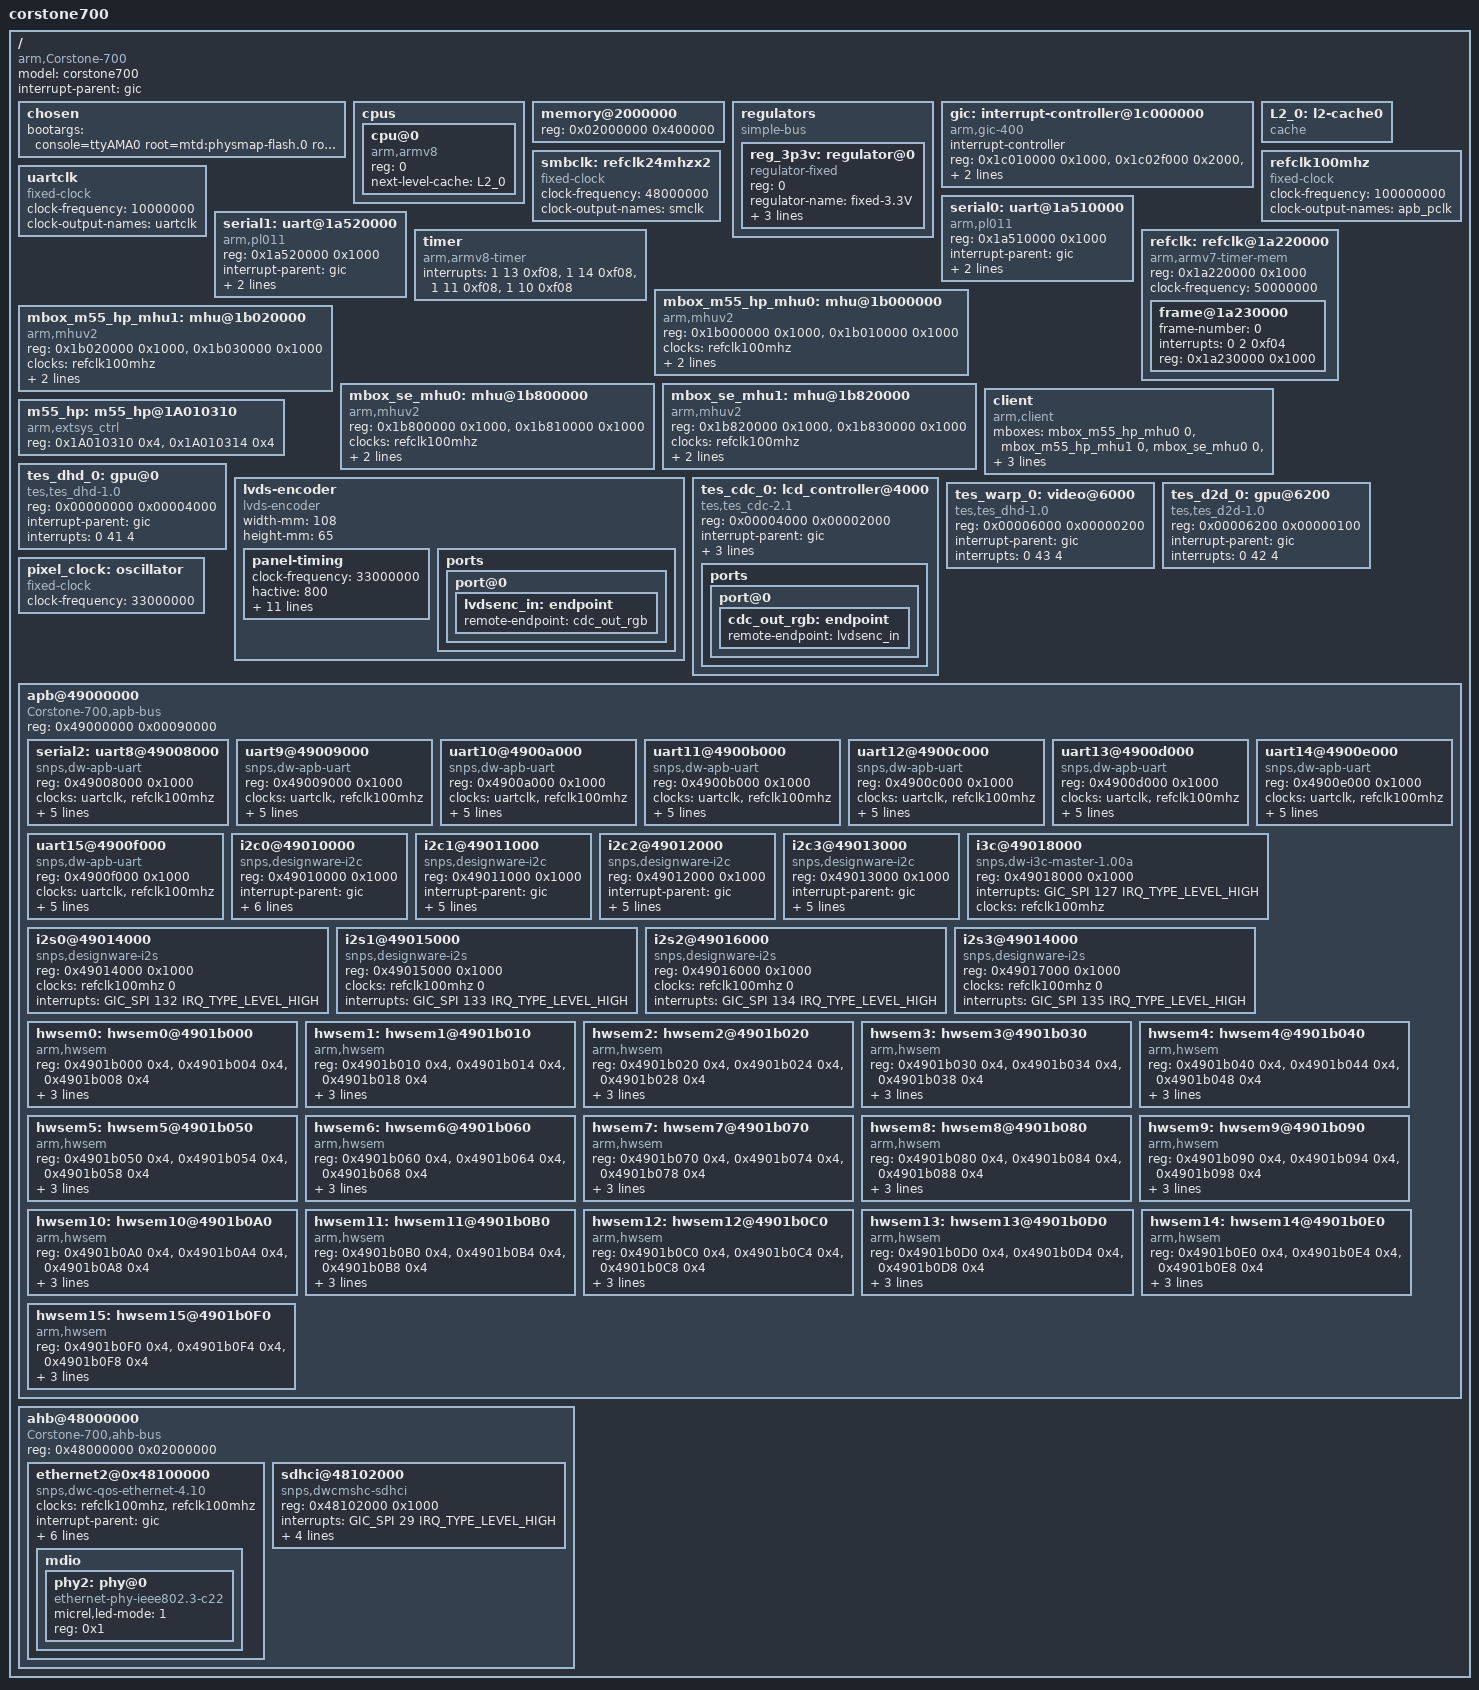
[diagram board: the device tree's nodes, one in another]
/*
 * Copyright (c) 2019, ARM Limited and Contributors. All rights reserved.
 *
 * SPDX-License-Identifier: BSD-3-Clause
 */

/dts-v1/;

#include <dt-bindings/interrupt-controller/arm-gic.h>

/ {
	model = "corstone700";
	compatible = "arm,Corstone-700";
	interrupt-parent = <&gic>;
	#address-cells = <1>;
	#size-cells = <1>;

	chosen {
		bootargs = "console=ttyAMA0 \
		root=mtd:physmap-flash.0 \
		ro \
		loglevel=9";
	};

	cpus {
		#address-cells = <1>;
		#size-cells = <0>;

		cpu@0 {
			device_type = "cpu";
			compatible = "arm,armv8";
			reg = <0>;
			next-level-cache = <&L2_0>;
		};
	};

	memory@2000000 {
		device_type = "memory";
		reg = <0x02000000 0x400000>;
	};

	regulators {
		compatible = "simple-bus";
		#address-cells = <1>;
		#size-cells = <0>;
		reg_3p3v: regulator@0 {
			compatible = "regulator-fixed";
			reg = <0>;
			regulator-name = "fixed-3.3V";
			regulator-min-microvolt = <3300000>;
			regulator-max-microvolt = <3300000>;
			regulator-always-on;
		};
	};

	gic: interrupt-controller@1c000000 {
		compatible = "arm,gic-400";
		#interrupt-cells = <3>;
		#address-cells = <0>;
		interrupt-controller;
		reg =	<0x1c010000 0x1000>,
			<0x1c02f000 0x2000>,
			<0x1c04f000 0x1000>,
			<0x1c06f000 0x2000>;
		interrupts = <1 9 0xf08>;
	};

	L2_0: l2-cache0 {
		compatible = "cache";
	};

	refclk100mhz: refclk100mhz {
		compatible = "fixed-clock";
		#clock-cells = <0>;
		clock-frequency = <100000000>;
		clock-output-names = "apb_pclk";
	};

	smbclk: refclk24mhzx2 {
		/* Reference 24MHz clock x 2 */
		compatible = "fixed-clock";
		#clock-cells = <0>;
		clock-frequency = <48000000>;
		clock-output-names = "smclk";
	};

	uartclk: uartclk {
		/* uart clock - 10MHz */
		compatible = "fixed-clock";
		#clock-cells = <0>;
		clock-frequency = <10000000>;
		clock-output-names = "uartclk";
	};

	serial0: uart@1a510000 {
		compatible = "arm,pl011", "arm,primecell";
		reg = <0x1a510000 0x1000>;
		interrupt-parent = <&gic>;
		interrupts = <0 19 4>;
		clocks = <&uartclk>, <&refclk100mhz>;
		clock-names = "uartclk", "apb_pclk";
	};

	serial1: uart@1a520000 {
		compatible = "arm,pl011", "arm,primecell";
		reg = <0x1a520000 0x1000>;
		interrupt-parent = <&gic>;
		interrupts = <0 20 4>;
		clocks = <&uartclk>, <&refclk100mhz>;
		clock-names = "uartclk", "apb_pclk";
	};

	timer {
		compatible = "arm,armv8-timer";
		interrupts =	<1 13 0xf08>,
				<1 14 0xf08>,
				<1 11 0xf08>,
				<1 10 0xf08>;
	};

	refclk: refclk@1a220000 {
		compatible = "arm,armv7-timer-mem";
		reg = <0x1a220000  0x1000>;
		clock-frequency = <50000000>;
		#address-cells = <1>;
		#size-cells = <1>;
		ranges;

		frame@1a230000 {
			frame-number = <0>;
			interrupts = <0 2 0xf04>;
			reg = <0x1a230000 0x1000>;
		};
	};

	mbox_m55_hp_mhu0: mhu@1b000000 {
		compatible = "arm,mhuv2","arm,primecell";
		reg = <0x1b000000 0x1000>,
		      <0x1b010000 0x1000>;
		clocks = <&refclk100mhz>;
		clock-names = "apb_pclk";
		interrupts = <0 12 4>;
		interrupt-names = "mhu_rx";
		#mbox-cells = <1>;
		mbox-name = "arm-m55_hp-mhu0";
	};

	mbox_m55_hp_mhu1: mhu@1b020000 {
		compatible = "arm,mhuv2","arm,primecell";
		reg = <0x1b020000 0x1000>,
		      <0x1b030000 0x1000>;
		clocks = <&refclk100mhz>;
		clock-names = "apb_pclk";
		interrupts = <0 47 4>;
		interrupt-names = "mhu_rx";
		#mbox-cells = <1>;
		mbox-name = "arm-m55_hp-mhu1";
	};

	mbox_se_mhu0: mhu@1b800000 {
		compatible = "arm,mhuv2","arm,primecell";
		reg = <0x1b800000 0x1000>,
		      <0x1b810000 0x1000>;
		clocks = <&refclk100mhz>;
		clock-names = "apb_pclk";
		interrupts = <0 10 4>;
		interrupt-names = "mhu_rx";
		#mbox-cells = <1>;
		mbox-name = "arm-se-mhu0";
	};

	mbox_se_mhu1: mhu@1b820000 {
		compatible = "arm,mhuv2","arm,primecell";
		reg = <0x1b820000 0x1000>,
		      <0x1b830000 0x1000>;
		clocks = <&refclk100mhz>;
		clock-names = "apb_pclk";
		interrupts = <0 45 4>;
		interrupt-names = "mhu_rx";
		#mbox-cells = <1>;
		mbox-name = "arm-se-mhu1";
	};

	client {
		compatible = "arm,client";
		mboxes = <&mbox_m55_hp_mhu0 0>,
			 <&mbox_m55_hp_mhu1 0>,
			 <&mbox_se_mhu0 0>,
			 <&mbox_se_mhu1 0>;
		mbox-names = "m55_hp_mhu0", "m55_hp_mhu1", "se_mhu0", "se_mhu1";
	};

	m55_hp: m55_hp@1A010310 {
		compatible = "arm,extsys_ctrl";
		reg = <0x1A010310 0x4>,
		      <0x1A010314 0x4>;
		reg-names = "rstreg", "streg";
	};

	tes_dhd_0: gpu@0 {
		compatible = "tes,tes_dhd-1.0", "tes,dhd-1.0";
		reg = <0x00000000 0x00004000>;
		interrupt-parent = <&gic>;
		interrupts = <0 41 4>;
	};

	lvds-encoder {
		compatible = "lvds-encoder";
		width-mm = <108>;
		height-mm = <65>;

		panel-timing {
			clock-frequency = <33000000>;
			hactive = <800>;
			vactive = <480>;
			hfront-porch = <210>;
			hback-porch = <46>;
			hsync-len = <3>;
			vback-porch = <23>;
			vfront-porch = <22>;
			vsync-len = <3>;
			hsync-active = <0>;
			vsync-active = <0>;
			de-active = <1>;
			pixelclk-active = <1>;
		};

		ports {
			port@0 {
				lvdsenc_in: endpoint {
					remote-endpoint = <&cdc_out_rgb>;
				};
			};
		};
	};

	tes_cdc_0: lcd_controller@4000 {
		compatible = "tes,tes_cdc-2.1", "tes,cdc-2.1";
		reg = <0x00004000 0x00002000>;
		interrupt-parent = <&gic>;
		interrupts = <0 40 4>;
		clocks = <&pixel_clock>;
		max-clock-frequency = <108000000>;

		ports {
			port@0 {
				cdc_out_rgb: endpoint {
					remote-endpoint = <&lvdsenc_in>;
				};
			};
		};
	}; //end lcd_controller@0x00000000 (tes_cdc_0)

	tes_warp_0: video@6000 {
		compatible = "tes,tes_dhd-1.0", "tes,dhd-1.0";
		reg = <0x00006000 0x00000200>;
		interrupt-parent = <&gic>;
		interrupts = <0 43 4>;
	};

	tes_d2d_0: gpu@6200 {
		compatible = "tes,tes_d2d-1.0", "tes,d2d-1.0";
		reg = <0x00006200 0x00000100>;
		interrupt-parent = <&gic>;
		interrupts = <0 42 4>;
	};

	pixel_clock: oscillator {
		compatible = "fixed-clock";
		#clock-cells = <0>;
		clock-frequency = <33000000>;
	};

	/* ====== EXPMST0 APB ====== */
	apb@49000000{
		compatible = "Corstone-700,apb-bus","simple-bus";
		#address-cells = <1>;
		#size-cells = <1>;
		reg = <0x49000000 0x00090000>;
		ranges = <>;

		/* ====== DW UART ====== */
		serial2: uart8@49008000 {
			compatible = "snps,dw-apb-uart";
			reg = <0x49008000 0x1000>;
			clocks = <&uartclk>, <&refclk100mhz>;
			clock-names = "baudclk", "apb_pclk";
			interrupt-parent = <&gic>;
			interrupts = <GIC_SPI 115 IRQ_TYPE_LEVEL_HIGH>;
			snps,uart-16550-compatible;
			reg-shift = <2>;
			reg-io-width = <4>;
		};

		uart9@49009000 {
			compatible = "snps,dw-apb-uart";
			reg = <0x49009000 0x1000>;
			clocks = <&uartclk>, <&refclk100mhz>;
			clock-names = "baudclk", "apb_pclk";
			interrupt-parent = <&gic>;
			interrupts = <GIC_SPI 116 IRQ_TYPE_LEVEL_HIGH>;
			snps,uart-16550-compatible;
			reg-shift = <2>;
			reg-io-width = <4>;
		};

		uart10@4900a000 {
			compatible = "snps,dw-apb-uart";
			reg = <0x4900a000 0x1000>;
			clocks = <&uartclk>, <&refclk100mhz>;
			clock-names = "baudclk", "apb_pclk";
			interrupt-parent = <&gic>;
			interrupts = <GIC_SPI 117 IRQ_TYPE_LEVEL_HIGH>;
			snps,uart-16550-compatible;
			reg-shift = <2>;
			reg-io-width = <4>;
		};

		uart11@4900b000 {
			compatible = "snps,dw-apb-uart";
			reg = <0x4900b000 0x1000>;
			clocks = <&uartclk>, <&refclk100mhz>;
			clock-names = "baudclk", "apb_pclk";
			interrupt-parent = <&gic>;
			interrupts = <GIC_SPI 118 IRQ_TYPE_LEVEL_HIGH>;
			snps,uart-16550-compatible;
			reg-shift = <2>;
			reg-io-width = <4>;
		};

		uart12@4900c000 {
			compatible = "snps,dw-apb-uart";
			reg = <0x4900c000 0x1000>;
			clocks = <&uartclk>, <&refclk100mhz>;
			clock-names = "baudclk", "apb_pclk";
			interrupt-parent = <&gic>;
			interrupts = <GIC_SPI 119 IRQ_TYPE_LEVEL_HIGH>;
			snps,uart-16550-compatible;
			reg-shift = <2>;
			reg-io-width = <4>;
		};

		uart13@4900d000 {
			compatible = "snps,dw-apb-uart";
			reg = <0x4900d000 0x1000>;
			clocks = <&uartclk>, <&refclk100mhz>;
			clock-names = "baudclk", "apb_pclk";
			interrupt-parent = <&gic>;
			interrupts = <GIC_SPI 120 IRQ_TYPE_LEVEL_HIGH>;
			snps,uart-16550-compatible;
			reg-shift = <2>;
			reg-io-width = <4>;
		};

		uart14@4900e000 {
			compatible = "snps,dw-apb-uart";
			reg = <0x4900e000 0x1000>;
			clocks = <&uartclk>, <&refclk100mhz>;
			clock-names = "baudclk", "apb_pclk";
			interrupt-parent = <&gic>;
			interrupts = <GIC_SPI 121 IRQ_TYPE_LEVEL_HIGH>;
			snps,uart-16550-compatible;
			reg-shift = <2>;
			reg-io-width = <4>;
		};

		uart15@4900f000 {
			compatible = "snps,dw-apb-uart";
			reg = <0x4900f000 0x1000>;
			clocks = <&uartclk>, <&refclk100mhz>;
			clock-names = "baudclk", "apb_pclk";
			interrupt-parent = <&gic>;
			interrupts = <GIC_SPI 122 IRQ_TYPE_LEVEL_HIGH>;
			snps,uart-16550-compatible;
			reg-shift = <2>;
			reg-io-width = <4>;
		};

		/* ====== DW I2C ====== */
		i2c0@49010000 {
			#address-cells = <1>;
			#size-cells = <0>;
			compatible = "snps,designware-i2c";
			reg = <0x49010000 0x1000>;
			interrupt-parent = <&gic>;
			interrupts = <GIC_SPI 123 IRQ_TYPE_LEVEL_HIGH>;
			clocks = <&refclk100mhz>;
			clock-names = "pclk" ;
			clock-frequency = <100000>;
			i2c-sda-hold-time-ns = <300>;
			i2c-sda-falling-time-ns = <300>;
			i2c-scl-falling-time-ns = <300>;
		};

		i2c1@49011000 {
			#address-cells = <1>;
			#size-cells = <0>;
			compatible = "snps,designware-i2c";
			reg = <0x49011000 0x1000>;
			interrupt-parent = <&gic>;
			interrupts = <GIC_SPI 124 IRQ_TYPE_LEVEL_HIGH>;
			clocks = <&refclk100mhz>;
			clock-names = "pclk" ;
			//clock-frequency = <100000>;
			i2c-sda-hold-time-ns = <300>;
			i2c-sda-falling-time-ns = <300>;
			i2c-scl-falling-time-ns = <300>;
		};

		i2c2@49012000 {
			#address-cells = <1>;
			#size-cells = <0>;
			compatible = "snps,designware-i2c";
			reg = <0x49012000 0x1000>;
			interrupt-parent = <&gic>;
			interrupts = <GIC_SPI 125 IRQ_TYPE_LEVEL_HIGH>;
			clocks = <&refclk100mhz>;
			clock-names = "pclk" ;
			//clock-frequency = <100000>;
			i2c-sda-hold-time-ns = <300>;
			i2c-sda-falling-time-ns = <300>;
			i2c-scl-falling-time-ns = <300>;
		};

		i2c3@49013000 {
			#address-cells = <1>;
			#size-cells = <0>;
			compatible = "snps,designware-i2c";
			reg = <0x49013000 0x1000>;
			interrupt-parent = <&gic>;
			interrupts = <GIC_SPI 126 IRQ_TYPE_LEVEL_HIGH>;
			clocks = <&refclk100mhz>;
			clock-names = "pclk" ;
			//clock-frequency = <100000>;
			i2c-sda-hold-time-ns = <300>;
			i2c-sda-falling-time-ns = <300>;
			i2c-scl-falling-time-ns = <300>;
		};

		/* ====== DW I3C ====== */
		i3c@49018000 {
			compatible = "snps,dw-i3c-master-1.00a";
			#address-cells = <3>;
			#size-cells = <0>;
			reg = <0x49018000 0x1000>;
			interrupts = <GIC_SPI 127 IRQ_TYPE_LEVEL_HIGH>;
			clocks = <&refclk100mhz>;
		}; /* I3C End*/

		/*====== DW I2S ====== */
		i2s0@49014000 {
			compatible = "snps,designware-i2s";
			reg = <0x49014000 0x1000>;
			clocks = <&refclk100mhz 0>;
			clock-names = "i2sclk";
			#sound-dai-cells = <0>;
			interrupts = <GIC_SPI 132 IRQ_TYPE_LEVEL_HIGH>;
			//dmas = <&dma0 5>;
			//dma-names = "tx";
		};

		i2s1@49015000 {
			compatible = "snps,designware-i2s";
			reg = <0x49015000 0x1000>;
			clocks = <&refclk100mhz 0>;
			clock-names = "i2sclk";
			#sound-dai-cells = <0>;
			interrupts = <GIC_SPI 133 IRQ_TYPE_LEVEL_HIGH>;
			//dmas = <&dma0 5>;
			//dma-names = "tx";
		};

		i2s2@49016000 {
			compatible = "snps,designware-i2s";
			reg = <0x49016000 0x1000>;
			clocks = <&refclk100mhz 0>;
			clock-names = "i2sclk";
			#sound-dai-cells = <0>;
			interrupts = <GIC_SPI 134 IRQ_TYPE_LEVEL_HIGH>;
			//dmas = <&dma0 5>;
			//dma-names = "tx";
		};

		i2s3@49014000 {
			compatible = "snps,designware-i2s";
			reg = <0x49017000 0x1000>;
			clocks = <&refclk100mhz 0>;
			clock-names = "i2sclk";
			#sound-dai-cells = <0>;
			interrupts = <GIC_SPI 135 IRQ_TYPE_LEVEL_HIGH>;
			//dmas = <&dma0 5>;
			//dma-names = "tx";
		}; /* I2S END */

		/* Hardware Semaphore (HWSEM) */
		hwsem0: hwsem0@4901b000 {
			compatible = "arm,hwsem";
			reg = <0x4901b000 0x4>,
			      <0x4901b004 0x4>,
			      <0x4901b008 0x4>;
			reg-names = "hwsem_acq", "hwsem_rel", "hwsem_rst";
			interrupt-parent = <&gic>;
			interrupts = <0 96 4>;
			clocks = <&refclk100mhz>;
			clock-names = "pclk" ;
		};
		hwsem1: hwsem1@4901b010 {
			compatible = "arm,hwsem";
			reg = <0x4901b010 0x4>,
			      <0x4901b014 0x4>,
			      <0x4901b018 0x4>;
			reg-names = "hwsem_acq", "hwsem_rel", "hwsem_rst";
			interrupt-parent = <&gic>;
			interrupts = <0 97 4>;
			clocks = <&refclk100mhz>;
			clock-names = "pclk" ;
		};
		hwsem2: hwsem2@4901b020 {
			compatible = "arm,hwsem";
			reg = <0x4901b020 0x4>,
			      <0x4901b024 0x4>,
			      <0x4901b028 0x4>;
			reg-names = "hwsem_acq", "hwsem_rel", "hwsem_rst";
			interrupt-parent = <&gic>;
			interrupts = <0 98 4>;
			clocks = <&refclk100mhz>;
			clock-names = "pclk" ;
		};
		hwsem3: hwsem3@4901b030 {
			compatible = "arm,hwsem";
			reg = <0x4901b030 0x4>,
			      <0x4901b034 0x4>,
			      <0x4901b038 0x4>;
			reg-names = "hwsem_acq", "hwsem_rel", "hwsem_rst";
			interrupt-parent = <&gic>;
			interrupts = <0 99 4>;
			clocks = <&refclk100mhz>;
			clock-names = "pclk" ;
		};
		hwsem4: hwsem4@4901b040 {
			compatible = "arm,hwsem";
			reg = <0x4901b040 0x4>,
			      <0x4901b044 0x4>,
			      <0x4901b048 0x4>;
			reg-names = "hwsem_acq", "hwsem_rel", "hwsem_rst";
			interrupt-parent = <&gic>;
			interrupts = <0 100 4>;
			clocks = <&refclk100mhz>;
			clock-names = "pclk" ;
		};
		hwsem5: hwsem5@4901b050 {
			compatible = "arm,hwsem";
			reg = <0x4901b050 0x4>,
			      <0x4901b054 0x4>,
			      <0x4901b058 0x4>;
			reg-names = "hwsem_acq", "hwsem_rel", "hwsem_rst";
			interrupt-parent = <&gic>;
			interrupts = <0 101 4>;
			clocks = <&refclk100mhz>;
			clock-names = "pclk" ;
		};
		hwsem6: hwsem6@4901b060 {
			compatible = "arm,hwsem";
			reg = <0x4901b060 0x4>,
			      <0x4901b064 0x4>,
			      <0x4901b068 0x4>;
			reg-names = "hwsem_acq", "hwsem_rel", "hwsem_rst";
			interrupt-parent = <&gic>;
			interrupts = <0 102 4>;
			clocks = <&refclk100mhz>;
			clock-names = "pclk" ;
		};
		hwsem7: hwsem7@4901b070 {
			compatible = "arm,hwsem";
			reg = <0x4901b070 0x4>,
			      <0x4901b074 0x4>,
			      <0x4901b078 0x4>;
			reg-names = "hwsem_acq", "hwsem_rel", "hwsem_rst";
			interrupt-parent = <&gic>;
			interrupts = <0 103 4>;
			clocks = <&refclk100mhz>;
			clock-names = "pclk" ;
		};
		hwsem8: hwsem8@4901b080 {
			compatible = "arm,hwsem";
			reg = <0x4901b080 0x4>,
			      <0x4901b084 0x4>,
			      <0x4901b088 0x4>;
			reg-names = "hwsem_acq", "hwsem_rel", "hwsem_rst";
			interrupt-parent = <&gic>;
			interrupts = <0 104 4>;
			clocks = <&refclk100mhz>;
			clock-names = "pclk" ;
		};
		hwsem9: hwsem9@4901b090 {
			compatible = "arm,hwsem";
			reg = <0x4901b090 0x4>,
			      <0x4901b094 0x4>,
			      <0x4901b098 0x4>;
			reg-names = "hwsem_acq", "hwsem_rel", "hwsem_rst";
			interrupt-parent = <&gic>;
			interrupts = <0 105 4>;
			clocks = <&refclk100mhz>;
			clock-names = "pclk" ;
		};
		hwsem10: hwsem10@4901b0A0 {
			compatible = "arm,hwsem";
			reg = <0x4901b0A0 0x4>,
			      <0x4901b0A4 0x4>,
			      <0x4901b0A8 0x4>;
			reg-names = "hwsem_acq", "hwsem_rel", "hwsem_rst";
			interrupt-parent = <&gic>;
			interrupts = <0 106 4>;
			clocks = <&refclk100mhz>;
			clock-names = "pclk" ;
		};
		hwsem11: hwsem11@4901b0B0 {
			compatible = "arm,hwsem";
			reg = <0x4901b0B0 0x4>,
			      <0x4901b0B4 0x4>,
			      <0x4901b0B8 0x4>;
			reg-names = "hwsem_acq", "hwsem_rel", "hwsem_rst";
			interrupt-parent = <&gic>;
			interrupts = <0 107 4>;
			clocks = <&refclk100mhz>;
			clock-names = "pclk" ;
		};
		hwsem12: hwsem12@4901b0C0 {
			compatible = "arm,hwsem";
			reg = <0x4901b0C0 0x4>,
			      <0x4901b0C4 0x4>,
			      <0x4901b0C8 0x4>;
			reg-names = "hwsem_acq", "hwsem_rel", "hwsem_rst";
			interrupt-parent = <&gic>;
			interrupts = <0 108 4>;
			clocks = <&refclk100mhz>;
			clock-names = "pclk" ;
		};
		hwsem13: hwsem13@4901b0D0 {
			compatible = "arm,hwsem";
			reg = <0x4901b0D0 0x4>,
			      <0x4901b0D4 0x4>,
			      <0x4901b0D8 0x4>;
			reg-names = "hwsem_acq", "hwsem_rel", "hwsem_rst";
			interrupt-parent = <&gic>;
			interrupts = <0 109 4>;
			clocks = <&refclk100mhz>;
			clock-names = "pclk" ;
		};
		hwsem14: hwsem14@4901b0E0 {
			compatible = "arm,hwsem";
			reg = <0x4901b0E0 0x4>,
			      <0x4901b0E4 0x4>,
			      <0x4901b0E8 0x4>;
			reg-names = "hwsem_acq", "hwsem_rel", "hwsem_rst";
			interrupt-parent = <&gic>;
			interrupts = <0 110 4>;
			clocks = <&refclk100mhz>;
			clock-names = "pclk" ;
		};
		hwsem15: hwsem15@4901b0F0 {
			compatible = "arm,hwsem";
			reg = <0x4901b0F0 0x4>,
			      <0x4901b0F4 0x4>,
			      <0x4901b0F8 0x4>;
			reg-names = "hwsem_acq", "hwsem_rel", "hwsem_rst";
			interrupt-parent = <&gic>;
			interrupts = <0 111 4>;
			clocks = <&refclk100mhz>;
			clock-names = "pclk" ;
		}; /* Hardware Semaphore END */
	};  /* APB END*/

	ahb@48000000{
		compatible = "Corstone-700,ahb-bus","simple-bus";
		#address-cells = <1>;
		#size-cells = <1>;
		reg = <0x48000000 0x02000000>;
		ranges = <>;

		ethernet2@0x48100000 {
			clock-names = "phy_ref_clk", "apb_pclk";
			clocks = <&refclk100mhz>, <&refclk100mhz>;
			compatible = "snps,dwc-qos-ethernet-4.10";
			interrupt-parent = <&gic>;
			interrupts = <GIC_SPI 144 IRQ_TYPE_LEVEL_HIGH>;
			reg = <0x48100000 0x2000>;
			phy-handle = <&phy2>;
			max-speed = <100>;
			phy-mode = "rmii";
			mac-address = [92 60 04 02 c3 e6];
			mdio{
				#address-cells = <0x1>;
				#size-cells = <0x0>;
				phy2: phy@0{
					compatible = "ethernet-phy-ieee802.3-c22";
					device_type = "ethernet-phy";
					micrel,led-mode = <1>;
					reg = <0x1>;
				};
			};
		}; /*End of ethernet */

		sdhci@48102000 {
			compatible = "snps,dwcmshc-sdhci";
			reg = <0x48102000 0x1000>;
			interrupts = <GIC_SPI 29 IRQ_TYPE_LEVEL_HIGH>;
			clocks = <&refclk100mhz>, <&refclk100mhz>;
			clock-names = "core", "bus";
			bus-width = <8>;
			vmmc-supply = <&reg_3p3v>;
			vqmmc-supply = <&reg_3p3v>;
		};
	};
};
